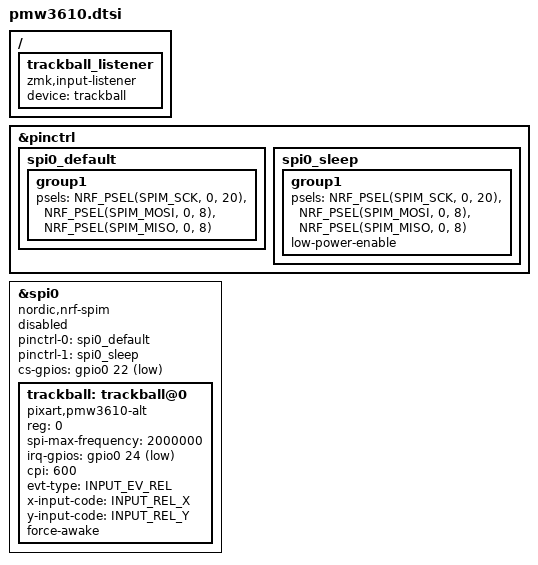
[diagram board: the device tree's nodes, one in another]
/* 
    For the *peripheral* side that has SPI pointing device with it. Not even dongle.overlay should have this.
    What's here: pinctrl & trackball input device node (SPI) for right & dongle side.
*/

&pinctrl {
    spi0_default: spi0_default {
        group1 {
            psels = <NRF_PSEL(SPIM_SCK, 0, 20)>, //SCLK
                <NRF_PSEL(SPIM_MOSI, 0, 8)>,     //SDIO
                <NRF_PSEL(SPIM_MISO, 0, 8)>;     //SDIO
        };
    };

    spi0_sleep: spi0_sleep {
        group1 {
            psels = <NRF_PSEL(SPIM_SCK, 0, 20)>, //SCLK
                <NRF_PSEL(SPIM_MOSI, 0, 8)>,     //SDIO
                <NRF_PSEL(SPIM_MISO, 0, 8)>;     //SDIO
            low-power-enable;
        };
    };
};

#include <zephyr/dt-bindings/input/input-event-codes.h>

&spi0 {
    status = "disabled";
    compatible = "nordic,nrf-spim";
    pinctrl-0 = <&spi0_default>;
    pinctrl-1 = <&spi0_sleep>;
    pinctrl-names = "default", "sleep";
    cs-gpios = <&gpio0 22 GPIO_ACTIVE_LOW>; //nCS

    trackball: trackball@0 {
        status = "okay";
        compatible = "pixart,pmw3610-alt";
        reg = <0>; // refers to the first SPI slave device
        spi-max-frequency = <2000000>;
        irq-gpios = <&gpio0 24 (GPIO_ACTIVE_LOW | GPIO_PULL_UP)>; //MOT
        cpi = <600>;

        /*   optional features   */
        // swap-xy; /* optional */
        // invert-x; /* optional */
        // invert-y; /* optional */
        evt-type = <INPUT_EV_REL>;
        x-input-code = <INPUT_REL_X>;
        y-input-code = <INPUT_REL_Y>;

        force-awake;
        /* keep the sensor awake while ZMK activity state is ACTIVE,
           fallback to normal downshift mode after ZMK goes into IDLE / SLEEP mode.
           thus, the sensor would be a `wakeup-source` */

        // force-awake-4ms-mode;
        /* while force-awake is acitvated, enable this mode to force sampling per 
           4ms, where the default sampling rate is 8ms. */
        /* NOTE: apply this mode if you need 250Hz with direct USB connection. */
    };
};


/ {
  trackball_listener {
    compatible = "zmk,input-listener";
    device = <&trackball>;
    };
};
